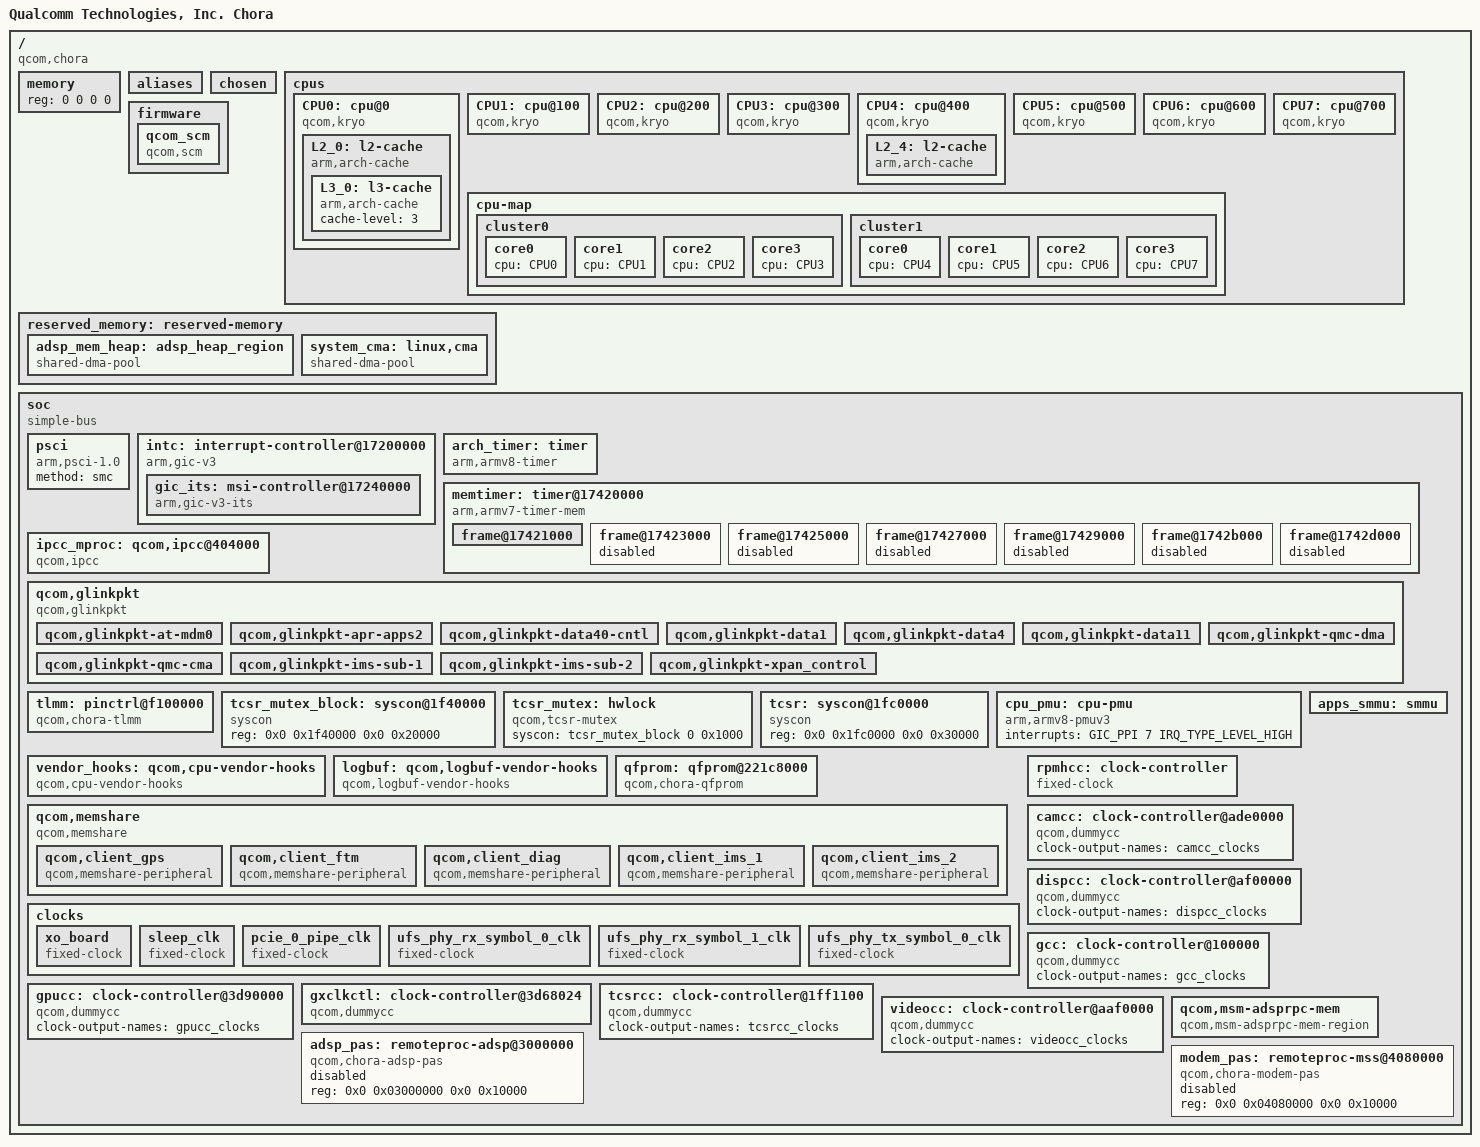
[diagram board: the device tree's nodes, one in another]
// SPDX-License-Identifier: BSD-3-Clause
/*
 * Copyright (c) Qualcomm Technologies, Inc. and/or its subsidiaries.
 */

#include <dt-bindings/clock/qcom,chora-camcc.h>
#include <dt-bindings/clock/qcom,chora-dispcc.h>
#include <dt-bindings/clock/qcom,chora-gcc.h>
#include <dt-bindings/clock/qcom,chora-gpucc.h>
#include <dt-bindings/clock/qcom,chora-tcsrcc.h>
#include <dt-bindings/clock/qcom,chora-videocc.h>
#include <dt-bindings/clock/qcom,rpmh.h>
#include <dt-bindings/interrupt-controller/arm-gic.h>

/ {
	model = "Qualcomm Technologies, Inc. Chora";
	compatible = "qcom,chora";
	qcom,msm-id = <724 0x10000>;
	interrupt-parent = <&intc>;

	#address-cells = <2>;
	#size-cells = <2>;
	memory { device_type = "memory"; reg = <0 0 0 0>; };

	aliases { };

	chosen: chosen {
		bootargs = "nokaslr kpti=0 log_buf_len=256K swiotlb=0 earlycon=qcom_geni,0x00a94000";
		stdout-path = "serial0:115200n8";
	};

	cpus {
		#address-cells = <2>;
		#size-cells = <0>;

		CPU0: cpu@0 {
			device_type = "cpu";
			compatible = "qcom,kryo";
			reg = <0x0 0x0>;
			enable-method = "psci";
			next-level-cache = <&L2_0>;

			L2_0: l2-cache {
				compatible = "arm,arch-cache";
				cache-level = <2>;
				next-level-cache = <&L3_0>;

				L3_0: l3-cache {
					compatible = "arm,arch-cache";
					cache-level = <3>;
				};
			};
		};

		CPU1: cpu@100 {
			device_type = "cpu";
			compatible = "qcom,kryo";
			reg = <0x0 0x100>;
			enable-method = "psci";
			next-level-cache = <&L2_0>;
		};

		CPU2: cpu@200 {
			device_type = "cpu";
			compatible = "qcom,kryo";
			reg = <0x0 0x200>;
			enable-method = "psci";
			next-level-cache = <&L2_0>;
		};

		CPU3: cpu@300 {
			device_type = "cpu";
			compatible = "qcom,kryo";
			reg = <0x0 0x300>;
			enable-method = "psci";
			next-level-cache = <&L2_0>;
		};

		CPU4: cpu@400 {
			device_type = "cpu";
			compatible = "qcom,kryo";
			reg = <0x0 0x400>;
			enable-method = "psci";
			next-level-cache = <&L2_4>;

			L2_4: l2-cache {
				compatible = "arm,arch-cache";
				cache-level = <2>;
				next-level-cache = <&L3_0>;
			};
		};

		CPU5: cpu@500 {
			device_type = "cpu";
			compatible = "qcom,kryo";
			reg = <0x0 0x500>;
			enable-method = "psci";
			next-level-cache = <&L2_4>;
		};

		CPU6: cpu@600 {
			device_type = "cpu";
			compatible = "qcom,kryo";
			reg = <0x0 0x600>;
			enable-method = "psci";
			next-level-cache = <&L2_4>;
		};

		CPU7: cpu@700 {
			device_type = "cpu";
			compatible = "qcom,kryo";
			reg = <0x0 0x700>;
			enable-method = "psci";
			next-level-cache = <&L2_4>;
		};

		cpu-map {

			cluster0 {

				core0 {
					cpu = <&CPU0>;
				};

				core1 {
					cpu = <&CPU1>;
				};

				core2 {
					cpu = <&CPU2>;
				};

				core3 {
					cpu = <&CPU3>;
				};
			};

			cluster1 {

				core0 {
					cpu = <&CPU4>;
				};

				core1 {
					cpu = <&CPU5>;
				};

				core2 {
					cpu = <&CPU6>;
				};

				core3 {
					cpu = <&CPU7>;
				};
			};
		};
	};

	firmware: firmware {
		qcom_scm: qcom_scm { };
	};

	reserved_memory: reserved-memory { };

	soc: soc { };
};

&firmware {
	qcom_scm {
		compatible = "qcom,scm";
	};
};

#include "chora-reserved-memory.dtsi"

&reserved_memory {
	#address-cells = <2>;
	#size-cells = <2>;
	ranges;

	adsp_mem_heap: adsp_heap_region {
		compatible = "shared-dma-pool";
		alloc-ranges = <0x0 0x00000000 0x0 0xffffffff>;
		reusable;
		alignment = <0x0 0x400000>;
		size = <0x0 0xC00000>;
	};

	/* global autoconfigured region for contiguous allocations */
	system_cma: linux,cma {
		compatible = "shared-dma-pool";
		alloc-ranges = <0x0 0x00000000 0x0 0xffffffff>;
		reusable;
		alignment = <0x0 0x400000>;
		size = <0x0 0x2400000>;
		linux,cma-default;
	};
};

&soc {
	#address-cells = <2>;
	#size-cells = <2>;
	ranges = <0 0 0 0 0x10 0>;
	compatible = "simple-bus";

	psci: psci {
		compatible = "arm,psci-1.0";
		method = "smc";
	};

	intc: interrupt-controller@17200000 {
		compatible = "arm,gic-v3";
		#interrupt-cells = <3>;
		interrupt-controller;
		#redistributor-regions = <1>;
		redistributor-stride = <0x0 0x20000>;
		reg = <0x0 0x17200000 0x0 0x10000>,	/* GICD */
		      <0x0 0x17260000 0x0 0x100000>;	/* GICR * 8 */
		interrupts = <GIC_PPI 9 IRQ_TYPE_LEVEL_LOW>;

		#address-cells = <1>;
		#size-cells = <1>;
		ranges;
		gic_its: msi-controller@17240000 {
			compatible = "arm,gic-v3-its";
			msi-controller;
			#msi-cells = <1>;
			reg = <0x17240000 0x20000>;
		};
	};

	arch_timer: timer {
		compatible = "arm,armv8-timer";
		interrupts = <GIC_PPI 13 (GIC_CPU_MASK_SIMPLE(8) | IRQ_TYPE_LEVEL_LOW)>,
			     <GIC_PPI 14 (GIC_CPU_MASK_SIMPLE(8) | IRQ_TYPE_LEVEL_LOW)>,
			     <GIC_PPI 11 (GIC_CPU_MASK_SIMPLE(8) | IRQ_TYPE_LEVEL_LOW)>,
			     <GIC_PPI 10 (GIC_CPU_MASK_SIMPLE(8) | IRQ_TYPE_LEVEL_LOW)>;
		clock-frequency = <19200000>;
	};

	memtimer: timer@17420000 {
		compatible = "arm,armv7-timer-mem";
		reg = <0x0 0x17420000 0x0 0x1000>;
		clock-frequency = <19200000>;

		#address-cells = <1>;
		#size-cells = <1>;
		ranges;
		frame@17421000 {
			frame-number = <0>;
			interrupts = <GIC_SPI 8 IRQ_TYPE_LEVEL_HIGH>,
				     <GIC_SPI 6 IRQ_TYPE_LEVEL_HIGH>;
			reg = <0x17421000 0x1000>,
			      <0x17422000 0x1000>;
		};

		frame@17423000 {
			frame-number = <1>;
			interrupts = <GIC_SPI 9 IRQ_TYPE_LEVEL_HIGH>;
			reg = <0x17423000 0x1000>;
			status = "disabled";
		};

		frame@17425000 {
			frame-number = <2>;
			interrupts = <GIC_SPI 10 IRQ_TYPE_LEVEL_HIGH>;
			reg = <0x17425000 0x1000>;
			status = "disabled";
		};

		frame@17427000 {
			frame-number = <3>;
			interrupts = <GIC_SPI 11 IRQ_TYPE_LEVEL_HIGH>;
			reg = <0x17427000 0x1000>;
			status = "disabled";
		};

		frame@17429000 {
			frame-number = <4>;
			interrupts = <GIC_SPI 12 IRQ_TYPE_LEVEL_HIGH>;
			reg = <0x17429000 0x1000>;
			status = "disabled";
		};

		frame@1742b000 {
			frame-number = <5>;
			interrupts = <GIC_SPI 13 IRQ_TYPE_LEVEL_HIGH>;
			reg = <0x1742b000 0x1000>;
			status = "disabled";
		};

		frame@1742d000 {
			frame-number = <6>;
			interrupts = <GIC_SPI 14 IRQ_TYPE_LEVEL_HIGH>;
			reg = <0x1742d000 0x1000>;
			status = "disabled";
		};
	};

	ipcc_mproc: qcom,ipcc@404000 {
		compatible = "qcom,ipcc";
		reg = <0x0 0x404000 0x0 0x1000>;
		interrupts = <GIC_SPI 256 IRQ_TYPE_LEVEL_HIGH>;
		interrupt-controller;
		#interrupt-cells = <3>;
		#mbox-cells = <2>;
	};


	qcom,glinkpkt {
		compatible = "qcom,glinkpkt";

		qcom,glinkpkt-at-mdm0 {
			qcom,glinkpkt-edge = "mpss";
			qcom,glinkpkt-ch-name = "DS";
			qcom,glinkpkt-dev-name = "at_mdm0";
		};

		qcom,glinkpkt-apr-apps2 {
			qcom,glinkpkt-edge = "adsp";
			qcom,glinkpkt-ch-name = "apr_apps2";
			qcom,glinkpkt-dev-name = "apr_apps2";
		};

		qcom,glinkpkt-data40-cntl {
			qcom,glinkpkt-edge = "mpss";
			qcom,glinkpkt-ch-name = "DATA40_CNTL";
			qcom,glinkpkt-dev-name = "smdcntl8";
		};

		qcom,glinkpkt-data1 {
			qcom,glinkpkt-edge = "mpss";
			qcom,glinkpkt-ch-name = "DATA1";
			qcom,glinkpkt-dev-name = "smd7";
		};

		qcom,glinkpkt-data4 {
			qcom,glinkpkt-edge = "mpss";
			qcom,glinkpkt-ch-name = "DATA4";
			qcom,glinkpkt-dev-name = "smd8";
		};

		qcom,glinkpkt-data11 {
			qcom,glinkpkt-edge = "mpss";
			qcom,glinkpkt-ch-name = "DATA11";
			qcom,glinkpkt-dev-name = "smd11";
		};

		qcom,glinkpkt-qmc-dma {
			qcom,glinkpkt-edge = "mpss";
			qcom,glinkpkt-ch-name = "QMC_DMA_LINE";
			qcom,glinkpkt-dev-name = "qmc_dma";
			qcom,glinkpkt-enable-ch-close;
		};

		qcom,glinkpkt-qmc-cma {
			qcom,glinkpkt-edge = "mpss";
			qcom,glinkpkt-ch-name = "QMC_CMA_LINE";
			qcom,glinkpkt-dev-name = "qmc_cma";
			qcom,glinkpkt-enable-ch-close;
		};

		qcom,glinkpkt-ims-sub-1 {
			qcom,glinkpkt-edge = "mpss";
			qcom,glinkpkt-ch-name = "Ims_dc_sub1";
			qcom,glinkpkt-dev-name = "ims_dc_sub1";
			qcom,glinkpkt-enable-ch-close;
		};

		qcom,glinkpkt-ims-sub-2 {
			qcom,glinkpkt-edge = "mpss";
			qcom,glinkpkt-ch-name = "Ims_dc_sub2";
			qcom,glinkpkt-dev-name = "ims_dc_sub2";
			qcom,glinkpkt-enable-ch-close;
		};

		qcom,glinkpkt-xpan_control {
			qcom,glinkpkt-edge = "adsp";
			qcom,glinkpkt-ch-name = "bt_cp_ctrl";
			qcom,glinkpkt-dev-name = "bt_cp_ctrl";
		};
	};

	tlmm: pinctrl@f100000 {
		compatible = "qcom,chora-tlmm";
		reg = <0x0 0xf100000 0x0 0xf00000>;
		gpio-controller;
		#gpio-cells = <2>;
		interrupt-controller;
		#interrupt-cells = <2>;
		interrupts = <GIC_SPI 208 IRQ_TYPE_LEVEL_HIGH>;
		/* TODO: Add qcom,gpios-reserved */
	};

	tcsr_mutex_block: syscon@1f40000 {
		compatible = "syscon";
		reg = <0x0 0x1f40000 0x0 0x20000>;
	};

	tcsr_mutex: hwlock {
		compatible = "qcom,tcsr-mutex";
		syscon = <&tcsr_mutex_block 0 0x1000>;
		#hwlock-cells = <1>;
	};

	tcsr: syscon@1fc0000 {
		compatible = "syscon";
		reg = <0x0 0x1fc0000 0x0 0x30000>;
	};

	cpu_pmu: cpu-pmu {
		compatible = "arm,armv8-pmuv3";
		interrupts = <GIC_PPI 7 IRQ_TYPE_LEVEL_HIGH>;
	};

	vendor_hooks: qcom,cpu-vendor-hooks {
		compatible = "qcom,cpu-vendor-hooks";
	};

	logbuf: qcom,logbuf-vendor-hooks {
		compatible = "qcom,logbuf-vendor-hooks";
	};

	qfprom: qfprom@221c8000 {
		compatible = "qcom,chora-qfprom", "qcom,qfprom";
		reg = <0x0 0x221c8000 0x0 0x1000>;
		#address-cells = <1>;
		#size-cells = <1>;
		read-only;
		ranges;
	};

	qcom,memshare {
		compatible = "qcom,memshare";

		qcom,client_gps {
			compatible = "qcom,memshare-peripheral";
			client_name = "gps";
			qcom,peripheral-size = <0x0>;
			qcom,client-id = <0>;
			qcom,allocate-boot-time;
			label = "modem";
		};

		qcom,client_ftm {
			compatible = "qcom,memshare-peripheral";
			client_name = "ftm";
			qcom,peripheral-size = <0x0>;
			qcom,client-id = <2>;
			label = "modem";
		};

		qcom,client_diag {
			compatible = "qcom,memshare-peripheral";
			client_name = "diag";
			qcom,peripheral-size = <0x500000>;
			qcom,client-id = <1>;
			qcom,allocate-on-request;
			label = "modem";
		};

		qcom,client_ims_1 {
			compatible = "qcom,memshare-peripheral";
			client_name = "ims_1";
			qcom,peripheral-size = <0x100000>;
			qcom,client-id = <7>;
			qcom,allocate-on-request;
			qcom,shared;
			label = "modem";
		};

		qcom,client_ims_2 {
			compatible = "qcom,memshare-peripheral";
			client_name = "ims_2";
			qcom,peripheral-size = <0x100000>;
			qcom,client-id = <8>;
			qcom,allocate-on-request;
			qcom,shared;
			label = "modem";
		};
	};

	apps_smmu: smmu {};

	clocks {
		xo_board: xo_board {
			compatible = "fixed-clock";
			clock-frequency = <76800000>;
			clock-output-names = "xo_board";
			#clock-cells = <0>;
		};

		sleep_clk: sleep_clk {
			compatible = "fixed-clock";
			clock-frequency = <32000>;
			clock-output-names = "sleep_clk";
			#clock-cells = <0>;
		};

		pcie_0_pipe_clk: pcie_0_pipe_clk {
			compatible = "fixed-clock";
			clock-frequency = <1000>;
			clock-output-names = "pcie_0_pipe_clk";
			#clock-cells = <0>;
		};

		ufs_phy_rx_symbol_0_clk: ufs_phy_rx_symbol_0_clk {
			compatible = "fixed-clock";
			clock-frequency = <1000>;
			clock-output-names = "ufs_phy_rx_symbol_0_clk";
			#clock-cells = <0>;
		};

		ufs_phy_rx_symbol_1_clk: ufs_phy_rx_symbol_1_clk {
			compatible = "fixed-clock";
			clock-frequency = <1000>;
			clock-output-names = "ufs_phy_rx_symbol_1_clk";
			#clock-cells = <0>;
		};

		ufs_phy_tx_symbol_0_clk: ufs_phy_tx_symbol_0_clk {
			compatible = "fixed-clock";
			clock-frequency = <1000>;
			clock-output-names = "ufs_phy_tx_symbol_0_clk";
			#clock-cells = <0>;
		};
	};

	rpmhcc: clock-controller {
		compatible = "fixed-clock";
		clock-output-names = "rpmh_clocks";
		clock-frequency = <19200000>;
		#clock-cells = <1>;
	};

	camcc: clock-controller@ade0000 {
		compatible = "qcom,dummycc";
		clock-output-names = "camcc_clocks";
		#clock-cells = <1>;
		#reset-cells = <1>;
		#power-domain-cells = <1>;
	};

	dispcc: clock-controller@af00000 {
		compatible = "qcom,dummycc";
		clock-output-names = "dispcc_clocks";
		#clock-cells = <1>;
		#reset-cells = <1>;
		#power-domain-cells = <1>;
	};

	gcc: clock-controller@100000 {
		compatible = "qcom,dummycc";
		clock-output-names = "gcc_clocks";
		#clock-cells = <1>;
		#reset-cells = <1>;
		#power-domain-cells = <1>;
	};

	gpucc: clock-controller@3d90000 {
		compatible = "qcom,dummycc";
		clock-output-names = "gpucc_clocks";
		#clock-cells = <1>;
		#reset-cells = <1>;
		#power-domain-cells = <1>;
	};

	gxclkctl: clock-controller@3d68024 {
		compatible = "qcom,dummycc";
		#power-domain-cells = <1>;
	};

	tcsrcc: clock-controller@1ff1100 {
		compatible = "qcom,dummycc";
		clock-output-names = "tcsrcc_clocks";
		#clock-cells = <1>;
		#reset-cells = <1>;
	};

	videocc: clock-controller@aaf0000 {
		compatible = "qcom,dummycc";
		clock-output-names = "videocc_clocks";
		#clock-cells = <1>;
		#reset-cells = <1>;
		#power-domain-cells = <1>;
	};

	qcom,msm-adsprpc-mem {
		compatible = "qcom,msm-adsprpc-mem-region";
		memory-region = <&adsp_mem_heap>;
		restrict-access;
	};

	adsp_pas: remoteproc-adsp@3000000 {
		compatible = "qcom,chora-adsp-pas";
		reg = <0x0 0x03000000 0x0 0x10000>;

		status = "disabled";
	};

	modem_pas: remoteproc-mss@4080000 {
		compatible = "qcom,chora-modem-pas";
		reg = <0x0 0x04080000 0x0 0x10000>;

		status = "disabled";
	};
};

#include "chora-pinctrl.dtsi"
#include "chora-stub-regulators.dtsi"
